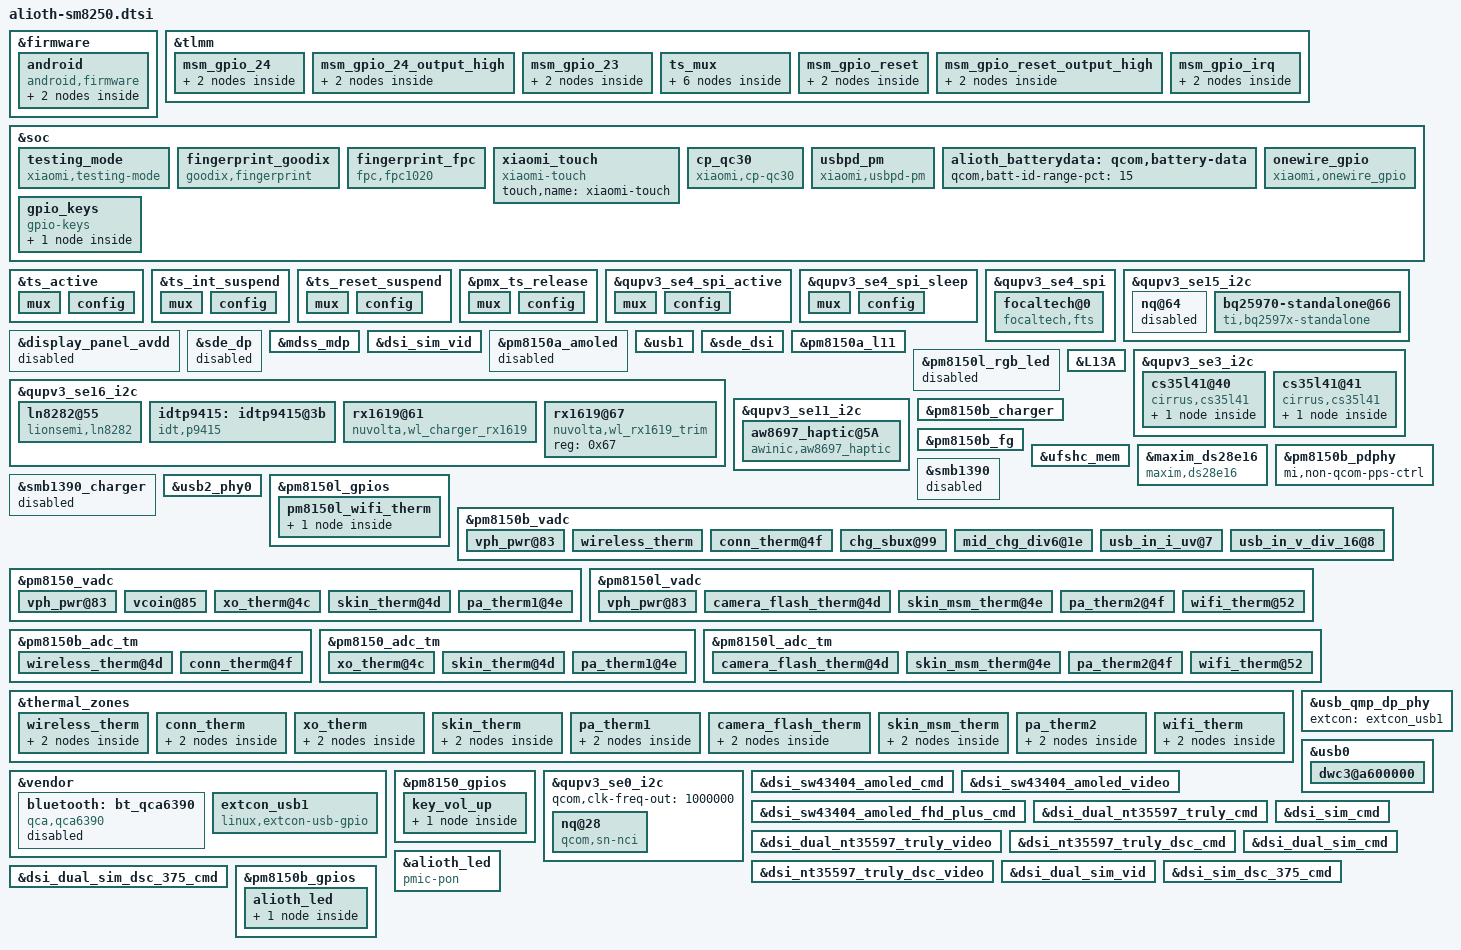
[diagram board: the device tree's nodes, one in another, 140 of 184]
/*
this file is for attribution only of alioth
*/

#include "alioth-pinctrl.dtsi"
#include "xiaomi-sm8250-common.dtsi"
#include "alioth-audio-overlay.dtsi"

&firmware {
	android {
		compatible = "android,firmware";
		vbmeta {
			compatible = "android,vbmeta";
			parts = "vbmeta,boot,system,vendor,dtbo";
		};

		fstab {
			compatible = "android,fstab";
		};
	};
};

/*IC int pin, rst pin init*/
&tlmm {
        /* GPIO_24: FP_RESET_N */
        msm_gpio_24: msm_gpio_24 {
                mux {
                         pins = "gpio24";
                         function = "gpio";
                };
                config {
                        pins = "gpio24";
                        drive-strength = <2>;
                        bias-disable;
                        output-low;
                };
        };
        /* GPIO_24 : FP_RESET_N, state device active*/
        msm_gpio_24_output_high: msm_gpio_24_output_high {
                mux {
                        pins = "gpio24";
                        function = "gpio";
                };
                config {
                        pins = "gpio24";
                        drive-strength = <2>;
                        bias-disable;
                        output-high;
                };
        };
        /* GPIO_23 : FP_INT_N */
        msm_gpio_23: msm_gpio_23 {
                mux {
                        pins = "gpio23";
                        function = "gpio";
                };
                config {
                        pins = "gpio23";
                        drive-strength = <2>;
                        bias-pull-down;
                };
        };

};

&soc {

	testing_mode {
		compatible = "xiaomi,testing-mode";
		status-gpio = <&tlmm 70 0x00>;
		debounce-time = <30>;
		pinctrl-names = "default";
		pinctrl-0 = <&test_mode_irq>;
	};

};

&ts_active {
	mux {
		pins = "gpio33", "gpio39";
		function = "gpio";
	};

	config {
		pins = "gpio33", "gpio39";
		drive-strength = <8>;
		bias-pull-up;
	};
};

&ts_int_suspend {
	mux {
		pins = "gpio39";
		function = "gpio";
	};

	config {
		pins = "gpio39";
		drive-strength = <2>;
		bias-pull-down;
	};
};

&ts_reset_suspend {
	mux {
		pins = "gpio33";
		function = "gpio";
	};

	config {
		pins = "gpio33";
		drive-strength = <2>;
		bias-pull-down;
	};
};

&pmx_ts_release {
	mux {
		pins = "gpio33", "gpio39";
		function = "gpio";
	};

	config {
		pins = "gpio33", "gpio39";
		drive-strength = <2>;
		bias-disable;
	};
};
&tlmm {
	ts_mux {
		ts_cs_active: ts_cs_active {
			mux {
				pins = "gpio11";
				function = "qup4";
			};

			config {
				pins = "gpio11";
				drive-strength = <16>;
				bias-pull-up;
			};
		};

		ts_cs_suspend: ts_cs_suspend {
			mux {
				pins = "gpio11";
				function = "gpio";
			};

			config {
				pins = "gpio11";
				drive-strength = <16>;
				bias-pull-up;
			};
		};
	};
};


&qupv3_se4_spi_active {
	mux {
		pins = "gpio8", "gpio9", "gpio10";
		function = "qup4";
	};

	config {
		pins = "gpio8", "gpio9", "gpio10";
		drive-strength = <6>;
		bias-pull-down;
	};
};

&qupv3_se4_spi_sleep {
	mux {
		pins = "gpio8", "gpio9", "gpio10";
		function = "gpio";
	};

	config {
		pins = "gpio8", "gpio9", "gpio10";
		drive-strength = <6>;
		bias-pull-down;
	};
};


&qupv3_se4_spi {
	status = "ok";
	pinctrl-0 = <&qupv3_se4_spi_active &ts_cs_active>;
	pinctrl-1 = <&qupv3_se4_spi_sleep &ts_cs_suspend>;
	focaltech@0 {
		status = "ok";
		compatible = "focaltech,fts";
		reg = <0x0>;
		spi-max-frequency = <10000000>;
		interrupt-parent = <&tlmm>;
		interrupts = <39 0x2008>;
		pinctrl-names = "pmx_ts_active", "pmx_ts_suspend", "pmx_ts_release";
		pinctrl-0 = <&ts_active>;
		pinctrl-1 = <&ts_int_suspend &ts_reset_suspend>;
		pinctrl-2 = <&pmx_ts_release>;
		vdd-supply = <&L10C>;
		vcc_i2c-supply = <&L1C>;
		focaltech,reset-gpio = <&tlmm 33 0x00>;
		focaltech,irq-gpio = <&tlmm 39 0x2008>;
		focaltech,max-touch-number = <10>;
		focaltech,display-coords = <0 0 8640 19200>;
		focaltech,open-min = <3000>;
		focaltech,touch-range-array = <1 5 10 15 20>;
		focaltech,touch-def-array = <3 3 3 3>;
		focaltech,touch-expert-array = <10 10 10 10
						20 20 15 10
						20 20 20 10>;
	};
};

&qupv3_se15_i2c {
	status = "ok";
	nq@64 {
		status = "disabled";
	};
};

&display_panel_avdd {
	status = "disabled";
};

&sde_dp {
	status = "disabled";
};

&mdss_mdp {
	connectors = <&sde_wb &sde_dsi &sde_dsi1 &sde_rscc>;
};

&dsi_sim_vid {
	qcom,panel-supply-entries = <&dsi_panel_pwr_supply_vci>;
	qcom,platform-reset-gpio = <&tlmm 12 0>;
};

&pm8150a_amoled {
	status = "disabled";
};

&usb1 {
        extcon = <&extcon_usb1>;
};

&sde_dsi {
	/delete-property/ vdd-supply;
	/delete-property/ avdd-supply;
	qcom,dsi-default-panel = <&dsi_sim_vid>;
	vci-supply = <&pm8150a_l11>;
};

&pm8150a_l11 {
	qcom,init-voltage = <3000000>;
	regulator-min-microvolt = <3000000>;
	regulator-max-microvolt = <3000000>;
};

&pm8150l_rgb_led {
	status = "disabled";
};

&soc {
	fingerprint_goodix {
		compatible = "goodix,fingerprint";
		goodix,gpio-reset = <&tlmm 24 GPIO_ACTIVE_LOW>;
		goodix,gpio-irq = <&tlmm 23 GPIO_ACTIVE_HIGH>;
		fp_vdd_vreg-supply = <&pm8150_l13>;
		status = "ok";
	};

	fingerprint_fpc {
		status = "ok";
		compatible = "fpc,fpc1020";
		interrupt-parent = <&tlmm>;
		interrupts = <23 0x0>;
		fpc,gpio_rst    = <&tlmm 24 0x0>;
		fpc,gpio_irq    = <&tlmm 23 0x0>;
		fp_vdd_vreg-supply = <&L13A>;
		pinctrl-names = "fpc1020_reset_reset",
			"fpc1020_reset_active",
			"fpc1020_irq_active";

		pinctrl-0 = <&msm_gpio_24>;
		pinctrl-1 = <&msm_gpio_24_output_high>;
		pinctrl-2 = <&msm_gpio_23>;

	};

/*
	fingerprint_3P0_VREG: fingerprint_3P0_VREG {
		compatible = "regulator-fixed";
		regulator-name = "fingerprint_3P0_VREG";
		startup-delay-us = <4000>;
		enable-active-high;
		gpio = <&tlmm 10 0>;
		regulator-always-on;
	};
*/
	xiaomi_touch {
		compatible = "xiaomi-touch";
		status = "ok";
		touch,name = "xiaomi-touch";
	};

};

&L13A {
	regulator-min-microvolt = <3304000>;
	regulator-max-microvolt = <3304000>;
	qcom,init-voltage = <3304000>;
	regulator-always-on;
};

&tlmm {
		/* FP_RESET_N */
	msm_gpio_reset: msm_gpio_reset {
		mux {
			pins = "gpio24";
			function = "gpio";
		};
		config {
			pins = "gpio24";
			drive-strength = <2>;
			bias-disable;
			output-low;
		};
	};
		/* FP_RESET_N, state device active*/
	msm_gpio_reset_output_high: msm_gpio_reset_output_high {
		mux {
			pins = "gpio24";
			function = "gpio";
		};
		config {
			pins = "gpio24";
			drive-strength = <2>;
			bias-disable;
			output-high;
		};
	};
		/* FP_INT_N */
	msm_gpio_irq: msm_gpio_irq {
		mux {
			pins = "gpio23";
			function = "gpio";
		};
		config {
			pins = "gpio23";
			drive-strength = <2>;
			bias-pull-down;
		};
	};
};

&qupv3_se15_i2c {
	#address-cells = <1>;
	#size-cells = <0>;
	status = "ok";
	bq25970-standalone@66 {
		compatible = "ti,bq2597x-standalone";
		reg = <0x66>;
		interrupt-parent = <&tlmm>;
		interrupts = <68 0x2002>;
		pinctrl-names = "default";
		pinctrl-0 = <&bq2597x_master_int_default>;

		/*ti,bq2597x,bat-ovp-disable;*/
		ti,bq2597x,bat-ovp-alarm-disable;
		ti,bq2597x,bat-ocp-disable;
		ti,bq2597x,bat-ocp-alarm-disable;
		ti,bq2597x,bat-ucp-alarm-disable;
		ti,bq2597x,bat-ucp-disable;

		/*ti,bq2597x,bus-ovp-alarm-disable;
		ti,bq2597x,bus-ocp-disable;
		ti,bq2597x,bus-ocp-alarm-disable;*/
		ti,bq2597x,bat-therm-disable;
		ti,bq2597x,bus-therm-disable;
		ti,bq2597x,die-therm-disable;

		ti,bq2597x,bat-ovp-threshold = <4525>;
		ti,bq2597x,bat-ovp-alarm-threshold = <4525>;
		//ti,bq2597x,bat-ocp-threshold = <8000>;
		//ti,bq2597x,bat-ocp-alarm-threshold = <7500>;

		ti,bq2597x,bus-ovp-threshold = <12000>;
		ti,bq2597x,bus-ovp-alarm-threshold = <11000>;
		ti,bq2597x,bus-ocp-threshold = <3750>;
		ti,bq2597x,bus-ocp-alarm-threshold = <3500>;

		//ti,bq2597x,bat-ucp-alarm-threshold = <2000>;

		ti,bq2597x,bat-therm-threshold = <0x15>;/*4.1%*/
		ti,bq2597x,bus-therm-threshold = <0x15>;/*4.1%*/
		ti,bq2597x,die-therm-threshold = <145>;

		ti,bq2597x,ac-ovp-threshold = <14>;
		//ti,bq2597x,sense-resistor-mohm = <2>;
	};
};

&qupv3_se16_i2c {
	status = "ok";
	ln8282@55 {
		compatible = "lionsemi,ln8282";
		status = "ok";
		reg = <0x55>;
		ln,enable = <&tlmm 156 0x00>;
		ln,irq = <&tlmm 158 0x00>;
		pinctrl-names = "ln8282_active","ln8282_suspend";
		pinctrl-0 = <&ln8282_enable_active>;
		pinctrl-1 = <&ln8282_enable_suspend>;
	};

	idtp9415: idtp9415@3b {
		compatible = "idt,p9415";
		status = "ok";
		reg = <0x3b>;
		idt,irq = <&tlmm 157 0x00>;
		idt,enable = <&tlmm 155 0x00>;
		idt,reverse-enable = <&tlmm 154 0x00>;
		idt,wpc-det = <&pm8150b_gpios 7 GPIO_ACTIVE_HIGH>;
		pinctrl-names = "default", "idt_active", "idt_suspend";
		pinctrl-0 = <&power_good_default>;
		pinctrl-1 = <&idt_int_active &idt_enable_active &txon_enable_active>;
		pinctrl-2 = <&idt_int_suspend &idt_enable_suspend &txon_enable_suspend>;
		mi,wireless-by-usbin;
		mi,only-idt-on-cmi;
	};

	rx1619@61 {
		compatible = "nuvolta,wl_charger_rx1619";
		reg = <0x61>;
		status = "ok";
		rx,irq_gpio = <&tlmm 157 0x00>;
		rx,tx_on_gpio = <&tlmm 154 0x00>;
		rx,power_good = <&pm8150b_gpios 7 GPIO_ACTIVE_HIGH>;
		rx,enable = <&tlmm 155 0x00>;
		pinctrl-names = "default","nu_active","nu_suspend";
		pinctrl-0 = <&power_good_default>;
		pinctrl-1 = <&nu_int_active &txon_enable_active &nu_sleep_active>;
		pinctrl-2 = <&nu_int_suspend &txon_enable_suspend &nu_sleep_suspend>;
		mi,wireless-by-usbin;
	};

	rx1619@67 {
		compatible = "nuvolta,wl_rx1619_trim";
		reg = <0x67>;
		status = "ok";
	};
};

&qupv3_se3_i2c {
	status = "ok";

        /* Speaker */
	cs35l41@40 {
		#sound-dai-cells = <1>;
		compatible = "cirrus,cs35l41";
		reset-gpios = <&tlmm 114 0>;
		reg = <0x40>;
		pinctrl-names = "cs35l41_irq_speaker";
		pinctrl-0 = <&cs35l41_int_speaker>;
		interrupt-parent = <&tlmm>;
		interrupts = <113 8>;
		cirrus,temp-warn_threshold = <3>;
		cirrus,boost-peak-milliamp = <4000>;
		cirrus,boost-ind-nanohenry = <1000>;
		cirrus,boost-cap-microfarad = <15>;
		cirrus,asp-sdout-hiz = <3>;
		//cirrus,right-channel-amp;
		sound-name-prefix = "RCV";
		cirrus,gpio-config2 {
			cirrus,gpio-src-select = <0x4>;
			cirrus,gpio-output-enable;
		};

	};
	/* Receiver */
	cs35l41@41 {
		#sound-dai-cells = <1>;
		compatible = "cirrus,cs35l41";
		reset-gpios = <&tlmm 114 0>;
		reg = <0x41>;
		pinctrl-names = "cs35l41_irq_speaker_rcv";
		pinctrl-0 = <&cs35l41_int_speaker_rcv>;
		interrupt-parent = <&tlmm>;
		interrupts = <112 8>;
		cirrus,temp-warn_threshold = <3>;
		cirrus,boost-peak-milliamp = <4000>;
		cirrus,boost-ind-nanohenry = <1000>;
		cirrus,boost-cap-microfarad = <15>;
		cirrus,right-channel-amp;
		cirrus,asp-sdout-hiz = <3>;
		//sound-name-prefix = "RCV";
		cirrus,gpio-config2 {
			cirrus,gpio-src-select = <0x4>;
			cirrus,gpio-output-enable;
		};

	};

};

&qupv3_se11_i2c {
	status = "ok";
	aw8697_haptic@5A {
		compatible = "awinic,aw8697_haptic";
		vib_bst_vol_default = < 0x11 >;
		vib_bst_vol_ram = < 0x11 >;
		vib_bst_vol_rtp = < 0x11 >;
		status = "ok";
	};
};
&pm8150b_charger {
	status = "ok";
	qcom,sec-charger-config = <0>;
	qcom,usb-icl-ua = <3000000>;
	qcom,fcc-max-ua = <5400000>;
	qcom,fv-max-uv = <4480000>;
	qcom,non-fcc-fv-max-uv = <4450000>;
	qcom,dc-icl-ua = <1000000>;
	qcom,auto-recharge-soc = <99>;
	qcom,chg-term-src = <1>;
	qcom,chg-term-current-ma = <(-220)>;
	//qcom,step-charging-enable;
	qcom,sw-jeita-enable;
	qcom,chg-warm-th= <450>;
	qcom,chg-cool-th= <150>;
	//qcom,suspend-input-on-debug-batt;
	qcom,usbpd-phandle = <&pm8150b_pdphy>;
	qcom,battery-data = <&alioth_batterydata>;
	mi,six-pin-step-chg-params = <4200000  5400000
				4450000  5400000
				4480000  4000000>;
	mi,six-pin-step-chg;
	mi,six-pin-soc-th = <85>;
	mi,fcc-batt-unverify-ua = <2000000>;
	mi,support-ffc;
	qcom,lpd-disable;
	mi,use-bq-pump;
	qcom,disable-suspend-on-collapse;
	qcom,distinguish-qc-class-ab;
//	qcom,support-conn-therm;
//	vbus-disable-gpio = <&tlmm 6 GPIO_ACTIVE_HIGH>;
//	pinctrl-names = "default", "vbus_disable_active", "vbus_disable_suspend";
//	pinctrl-0 = <&vbus_disable_suspend>;
//	pinctrl-1 = <&vbus_disable_active>;
//	pinctrl-2 = <&vbus_disable_suspend>;

	io-channels = <&pm8150b_vadc ADC_USB_IN_V_16>,
			<&pm8150b_vadc ADC_MID_CHG_DIV6>,
			<&pm8150b_vadc ADC_USB_IN_I>,
			<&pm8150b_vadc ADC_SBUx>,
			<&pm8150b_vadc ADC_VPH_PWR>,
			<&pm8150b_vadc ADC_AMUX_THM3_PU2>,
			<&pm8150b_vadc ADC_CHG_TEMP>;
	io-channel-names = "usb_in_voltage",
			"mid_voltage",
			"usb_in_current",
			"sbux_res",
			"vph_voltage",
			"conn_temp",
			"chg_temp";
	qcom,thermal-mitigation = <3000000 2800000 2600000 2400000 2200000 2100000 2000000
				   1800000 1600000 1500000 1400000 1200000 1000000 900000
				   800000 500000>;
	qcom,thermal-mitigation-icl
				= <2800000 2700000 2600000 2400000 2200000 2100000 2000000
				   1800000 1600000 1500000 1400000 1300000 1200000 1100000
				   950000 750000>;
	qcom,thermal-mitigation-dcp
				= <1800000 1800000 1800000 1800000 1800000 1800000 1800000
				   1800000 1800000 1700000 1600000 1400000 1200000 1100000
				   1100000 1000000>;
	qcom,thermal-mitigation-qc2
				= <1500000 1500000 1500000 1500000 1450000 1400000 1350000
				   1300000 1150000 1100000 1000000 900000 850000 750000
				   650000 500000>;
	qcom,thermal-fcc-qc3-normal
				= <3200000 3000000 2800000 2600000 2500000 2400000 2300000
				   2200000 2100000 1800000 1600000 1400000 1200000 1000000
				   750000 750000>;
	qcom,thermal-fcc-qc3-cp
				= <4800000 4600000 4400000 4200000 4000000 3800000 3600000
				   3400000 3000000 2600000 2400000 2200000 2000000 1300000
				   1000000 700000>;
	qcom,thermal-fcc-qc3-classb-cp
				= <5100000 4700000 4300000 4000000 3600000 3500000 3400000
				   3400000 3400000 3200000 2500000 2200000 2000000 700000
				   300000 100000>;
	qcom,thermal-mitigation-pd-base
				= <3000000 2800000 2600000 2400000 2200000 2000000 1800000
				   1600000 1600000 1400000 1200000 1100000 1050000 1000000
				   950000 500000>;
	qcom,thermal-fcc-pps-bq
				= <5400000 5300000 5200000 4900000 4800000 4500000 4200000
				   4000000 3800000 3500000 3200000 3000000 2500000 2000000
				   1500000 1000000>;
};

&pm8150b_fg {
	qcom,battery-data = <&alioth_batterydata>;
	qcom,rapid-soc-dec-en;
	qcom,five-pin-battery;
	qcom,soc-hi-res;
	qcom,sun-profile-only;
	qcom,soc_decimal_rate = <
		0  38
		10 35
		20 33
		30 33
		40 33
		50 33
		60 33
		70 30
		80 25
		90 20
		95 10 >;
	qcom,fg-sys-term-current = <(-500)>;
	qcom,fg-ffc-sys-term-current = <(-1500)>;
	qcom,ki-coeff-low-chg = <315>;
	qcom,ki-coeff-med-chg = <183>;
	qcom,fg-cutoff-voltage = <3400>;
	qcom,fg-cutoff-voltage-global = <3400>;
	qcom,fg-cutoff-current = <200>;
	qcom,fg-empty-voltage = <3100>;
	qcom,fg-batt-temp-hyst = <1>;
	qcom,fg-batt-temp-delta = <6>;
	qcom,soc-scale-vbatt-mv = <3600>;
	qcom,fg-force-load-profile;
	qcom,ki-coeff-chg-med-hi-thresh-ma = <1000>;
	qcom,ki-coeff-chg-low-med-thresh-ma = <500>;
	qcom,ffc-ki-coeff-chg-med-hi-thresh-ma = <3900>;
	qcom,ffc-ki-coeff-chg-low-med-thresh-ma = <3500>;
	qcom,fg-esr-cal-soc-thresh = <50 90>;
	qcom,fg-esr-cal-temp-thresh = <10 40>;
	qcom,fg-esr-timer-chg-fast = <0 7>;
	qcom,fg-esr-timer-dischg-fast = <0 7>;
	qcom,fg-esr-timer-chg-slow = <0 96>;
	qcom,fg-esr-timer-dischg-slow = <0 96>;
	qcom,fg-esr-cal-soc-thresh-2 = <50 4000>;
	qcom,fg-esr-cal-temp-thresh-2 = <10 40>;
	qcom,fg-esr-timer-chg-fast-2 = <0 7>;
	qcom,fg-esr-timer-dischg-fast-2 = <0 7>;
	qcom,fg-esr-timer-chg-slow-2 = <0 96>;
	qcom,fg-esr-timer-dischg-slow-2 = <0 96>;
	qcom,fg-esr-flt-sel = <2>;
	qcom,fg-esr-pulse-thresh-ma = <40>;
	qcom,fg-esr-meas-curr-ma = <60>;
	qcom,fg-ffc-esr-pulse-thresh-ma = <120>;
	qcom,fg-ffc-esr-meas-curr-ma = <100>;
	//qcom,fg-increase-100soc-time;
	qcom,fg-increase-100soc-time-2;
	qcom,shutdown-delay-enable;
};

&soc {
	cp_qc30 {
		compatible = "xiaomi,cp-qc30";
		status = "ok";
		mi,qc3-bat-volt-max = <4480>;
		mi,qc3-bat-curr-max = <3600>;
		mi,qc3-bus-volt-max = <12000>;
		mi,qc3-bus-curr-max = <2100>;
		mi,qc3-battery-warm-th = <450>;
		mi,use-qcom-gauge;
		mi,support-qc3p5-without-smb;
		//mi,cp-sec-enable;
	};

	usbpd_pm {
		compatible = "xiaomi,usbpd-pm";
		status = "ok";
		mi,pd-bat-volt-max = <4480>;
		mi,pd-bat-curr-max = <12500>;
		mi,pd-bus-volt-max = <12000>;
		mi,pd-bus-curr-max = <3000>;
		mi,pd-bus-curr-compensate  = <0>;
		mi,pd-non-ffc-bat-volt-max = <4450>;
		mi,pd-battery-warm-th = <450>;
		mi,step-charge-high-vol-curr-max = <5400000>;
		mi,use-qcom-gauge;
		//mi,cp-sec-enable;
		mi,therm-level-threshold = <12>;
	};

	alioth_batterydata: qcom,battery-data {
		qcom,batt-id-range-pct = <15>;
		#include "fg-gen4-batterydata-apollo-sun-5000mah.dtsi"
		#include "fg-gen4-batterydata-alioth-sunwoda-5000mah.dtsi"
		#include "fg-gen4-batterydata-alioth-atl-5000mah.dtsi"
	};

	onewire_gpio: onewire_gpio {
		compatible = "xiaomi,onewire_gpio";
		label = "xm_onewire";
		xiaomi,version = <1>;
		xiaomi,ow_gpio = <&tlmm 25 0x00>;
		mi,onewire-gpio-cfg-addr = <0x0F519000 0x4>;
		xiaomi,gpio_number = <25>;
		pinctrl-names = "onewire_active", "onewire_sleep";
		pinctrl-0 = <&onewire_gpio_active>;
		pinctrl-1 = <&onewire_gpio_sleep>;
		status = "ok";
	};
};

&ufshc_mem {
	vccq_set_npm = /bits/ 16 <0x1AD>;

	hsg4_synclength = /bits/ 16 <0x145 0x4F
				     0x1AD 0x4F
				     0x12C 0x4F>;

	status = "ok";
};

&maxim_ds28e16 {
	compatible = "maxim,ds28e16";
	label = "max_ds28e16";
	maxim,version = <1>;
	status = "ok";
	mi,factory-enable;
};

&pm8150b_pdphy {
	mi,non-qcom-pps-ctrl;
};

&smb1390 {
	status = "disabled";
};

&smb1390_charger {
	status = "disabled";
};

&usb2_phy0 {
	qcom,param-override-seq =
		<0xE5 0x6C
		 0xfa 0x70
		 0x2c 0x74>;
	qcom,global-param-override-seq =
		<0xE5 0x6C
		 0xfa 0x70
		 0x2c 0x74>;
};

&pm8150l_gpios {
	pm8150l_wifi_therm {
		pm8150l_wifi_therm_default: pm8150l_wifi_therm_default {
			pins = "gpio5";
			bias-high-impedance;
		};
	};
};

&pm8150b_vadc {
	#address-cells = <1>;
	#size-cells = <0>;

	vph_pwr@83 {
		reg = <ADC_VPH_PWR>;
		label = "vph_pwr";
		qcom,pre-scaling = <1 3>;
	};

	wireless_therm {
		reg = <ADC_AMUX_THM1_PU2>;
		label = "wireless_therm";
		qcom,ratiometric;
		qcom,hw-settle-time = <200>;
		qcom,pre-scaling = <1 1>;
	};

	conn_therm@4f {
		reg = <ADC_AMUX_THM3_PU2>;
		label = "conn_therm";
		qcom,ratiometric;
		qcom,hw-settle-time = <200>;
		qcom,pre-scaling = <1 1>;
	};

	chg_sbux@99 {
		reg = <ADC_SBUx>;
		label = "chg_sbux";
		qcom,pre-scaling = <1 3>;
	};

	mid_chg_div6@1e {
		reg = <ADC_MID_CHG_DIV6>;
		label = "chg_mid";
		qcom,pre-scaling = <1 6>;
	};

	usb_in_i_uv@7 {
		reg = <ADC_USB_IN_I>;
		label = "usb_in_i_uv";
		qcom,pre-scaling = <1 1>;
	};

	usb_in_v_div_16@8 {
		reg = <ADC_USB_IN_V_16>;
		label = "usb_in_v_div_16";
		qcom,pre-scaling = <1 16>;
	};
};

&pm8150_vadc {
	#address-cells = <1>;
	#size-cells = <0>;

	vph_pwr@83 {
		reg = <ADC_VPH_PWR>;
		label = "vph_pwr";
		qcom,pre-scaling = <1 3>;
	};

	vcoin@85 {
		reg = <ADC_VCOIN>;
		label = "vcoin";
		qcom,pre-scaling = <1 3>;
	};

	xo_therm@4c {
		reg = <ADC_XO_THERM_PU2>;
		label = "xo_therm";
		qcom,ratiometric;
		qcom,hw-settle-time = <200>;
		qcom,pre-scaling = <1 1>;
	};

	skin_therm@4d {
		reg = <ADC_AMUX_THM1_PU2>;
		label = "skin_therm";
		qcom,ratiometric;
		qcom,hw-settle-time = <200>;
		qcom,pre-scaling = <1 1>;
	};

	pa_therm1@4e {
		reg = <ADC_AMUX_THM2_PU2>;
		label = "pa_therm1";
		qcom,ratiometric;
		qcom,hw-settle-time = <200>;
		qcom,pre-scaling = <1 1>;
	};
};

&pm8150l_vadc {
	#address-cells = <1>;
	#size-cells = <0>;

	vph_pwr@83 {
		reg = <ADC_VPH_PWR>;
		label = "vph_pwr";
		qcom,pre-scaling = <1 3>;
	};

	camera_flash_therm@4d {
		reg = <ADC_AMUX_THM1_PU2>;
		label = "camera_flash_therm";
		qcom,ratiometric;
		qcom,hw-settle-time = <200>;
		qcom,pre-scaling = <1 1>;
	};

	skin_msm_therm@4e {
		reg = <ADC_AMUX_THM2_PU2>;
		label = "skin_msm_therm";
		qcom,ratiometric;
		qcom,hw-settle-time = <200>;
		qcom,pre-scaling = <1 1>;
	};

	pa_therm2@4f {
		reg = <ADC_AMUX_THM3_PU2>;
		label = "pa_therm2";
		qcom,ratiometric;
		qcom,hw-settle-time = <200>;
		qcom,pre-scaling = <1 1>;
	};

	wifi_therm@52 {
		reg = <ADC_GPIO1_PU2>;
		label = "wifi_therm";
		qcom,ratiometric;
		qcom,hw-settle-time = <200>;
		qcom,pre-scaling = <1 1>;
	};
};

&pm8150b_adc_tm {
	#address-cells = <1>;
	#size-cells = <0>;

	io-channels = <&pm8150b_vadc ADC_AMUX_THM1_PU2>,
			<&pm8150b_vadc ADC_AMUX_THM3_PU2>;

	wireless_therm@4d {
		reg = <ADC_AMUX_THM1_PU2>;
		qcom,ratiometric;
		qcom,hw-settle-time = <200>;
	};

	conn_therm@4f {
		reg = <ADC_AMUX_THM3_PU2>;
		qcom,ratiometric;
		qcom,hw-settle-time = <200>;
	};
};

&pm8150_adc_tm {
	#address-cells = <1>;
	#size-cells = <0>;

	io-channels = <&pm8150_vadc ADC_XO_THERM_PU2>,
			<&pm8150_vadc ADC_AMUX_THM1_PU2>,
			<&pm8150_vadc ADC_AMUX_THM2_PU2>;

	xo_therm@4c {
		reg = <ADC_XO_THERM_PU2>;
		qcom,ratiometric;
		qcom,hw-settle-time = <200>;
	};

	skin_therm@4d {
		reg = <ADC_AMUX_THM1_PU2>;
		qcom,ratiometric;
		qcom,hw-settle-time = <200>;
	};

	pa_therm1@4e {
		reg = <ADC_AMUX_THM2_PU2>;
		qcom,ratiometric;
		qcom,hw-settle-time = <200>;
	};
};

&pm8150l_adc_tm {
	#address-cells = <1>;
	#size-cells = <0>;

	camera_flash_therm@4d {
		reg = <ADC_AMUX_THM1_PU2>;
		qcom,ratiometric;
		qcom,hw-settle-time = <200>;
	};

	skin_msm_therm@4e {
		reg = <ADC_AMUX_THM2_PU2>;
		qcom,ratiometric;
		qcom,hw-settle-time = <200>;
	};

	pa_therm2@4f {
		reg = <ADC_AMUX_THM3_PU2>;
		qcom,ratiometric;
		qcom,hw-settle-time = <200>;
	};

	wifi_therm@52 {
		reg = <ADC_GPIO1_PU2>;
		qcom,ratiometric;
		qcom,hw-settle-time = <200>;
	};
};

&thermal_zones {
	wireless_therm {//place close to wireless charge RX ic
		polling-delay-passive = <0>;
		polling-delay = <0>;
		thermal-governor = "user_space";
		thermal-sensors = <&pm8150b_adc_tm ADC_AMUX_THM1_PU2>;
		wake-capable-sensor;
		trips {
			active-config0 {
				temperature = <125000>;
				hysteresis = <1000>;
				type = "passive";
			};
		};
	};

	conn_therm {//place close to type-c connector
		polling-delay-passive = <0>;
		polling-delay = <0>;
		thermal-governor = "user_space";
		thermal-sensors = <&pm8150b_adc_tm ADC_AMUX_THM3_PU2>;
		wake-capable-sensor;
		trips {
			active-config0 {
				temperature = <125000>;
				hysteresis = <1000>;
				type = "passive";
			};
		};
	};

	xo_therm {
		polling-delay-passive = <0>;
		polling-delay = <0>;
		thermal-governor = "user_space";
		thermal-sensors = <&pm8150_adc_tm ADC_XO_THERM_PU2>;
		wake-capable-sensor;
		trips {
			active-config0 {
				temperature = <125000>;
				hysteresis = <1000>;
				type = "passive";
			};
		};
	};

	skin_therm {
		polling-delay-passive = <0>;
		polling-delay = <0>;
		thermal-governor = "user_space";
		thermal-sensors = <&pm8150_adc_tm ADC_AMUX_THM1_PU2>;
		wake-capable-sensor;
		trips {
			active-config0 {
				temperature = <125000>;
				hysteresis = <1000>;
				type = "passive";
			};
		};
	};

	pa_therm1 {
		polling-delay-passive = <0>;
		polling-delay = <0>;
		thermal-governor = "user_space";
		thermal-sensors = <&pm8150_adc_tm ADC_AMUX_THM2_PU2>;
		wake-capable-sensor;
		trips {
			active-config0 {
				temperature = <125000>;
				hysteresis = <1000>;
				type = "passive";
			};
		};
	};

	camera_flash_therm {
		polling-delay-passive = <0>;
		polling-delay = <0>;
		thermal-governor = "user_space";
		thermal-sensors = <&pm8150l_adc_tm ADC_AMUX_THM1_PU2>;
		wake-capable-sensor;
		trips {
			active-config0 {
				temperature = <125000>;
				hysteresis = <1000>;
				type = "passive";
			};
		};
	};

	skin_msm_therm {
		polling-delay-passive = <0>;
		polling-delay = <0>;
		thermal-governor = "user_space";
		thermal-sensors = <&pm8150l_adc_tm ADC_AMUX_THM2_PU2>;
		wake-capable-sensor;
		trips {
			active-config0 {
				temperature = <125000>;
				hysteresis = <1000>;
				type = "passive";
			};
		};
	};

	pa_therm2 {
		polling-delay-passive = <0>;
		polling-delay = <0>;
		thermal-governor = "user_space";
		thermal-sensors = <&pm8150l_adc_tm ADC_AMUX_THM3_PU2>;
		wake-capable-sensor;
		trips {
			active-config0 {
				temperature = <125000>;
				hysteresis = <1000>;
				type = "passive";
			};
		};
	};

	wifi_therm {
		polling-delay-passive = <0>;
		polling-delay = <0>;
		thermal-governor = "user_space";
		thermal-sensors = <&pm8150l_adc_tm ADC_GPIO1_PU2>;
		wake-capable-sensor;
		trips {
			active-config0 {
				temperature = <125000>;
				hysteresis = <1000>;
				type = "passive";
			};
		};
	};
};

&vendor {
	bluetooth: bt_qca6390 {
		compatible = "qca,qca6390";
		pinctrl-names = "default";
		pinctrl-0 = <&bt_en_sleep>;
		qca,bt-reset-gpio = <&tlmm 21 0>; /* BT_EN */
		qca,wl-reset-gpio = <&tlmm 20 0>; /* WL_EN */
		qca,bt-vdd-aon-supply = <&pm8150_s6>;
		qca,bt-vdd-dig-supply = <&pm8150_s6>;
		qca,bt-vdd-rfa1-supply = <&pm8150_s5>;
		qca,bt-vdd-rfa2-supply = <&pm8150a_s8>;
		qca,bt-vdd-asd-supply = <&pm8150_l16>;

		qca,bt-vdd-aon-voltage-level = <950000 950000>;
		qca,bt-vdd-dig-voltage-level = <950000 952000>;
		qca,bt-vdd-rfa1-voltage-level = <1900000 1900000>;
		qca,bt-vdd-rfa2-voltage-level = <1350000 1350000>;
		qca,bt-vdd-asd-voltage-level = <3024000 3304000>;

		qca,bt-vdd-aon-current-level = <0>;
		qca,bt-vdd-dig-current-level = <0>;
		qca,bt-vdd-rfa1-current-level = <0>;
		qca,bt-vdd-rfa2-current-level = <0>;
		qca,bt-vdd-asd-current-level = <0>;
		status = "disabled";
	};

	extcon_usb1: extcon_usb1 {
		compatible = "linux,extcon-usb-gpio";
		vbus-gpio = <&pm8150_gpios 10 GPIO_ACTIVE_HIGH>;
		id-gpio = <&tlmm 91 GPIO_ACTIVE_HIGH>;
		vbus-out-gpio = <&pm8150_gpios 9 GPIO_ACTIVE_HIGH>;

		pinctrl-names = "default";
		pinctrl-0 = <&usb2_vbus_det_default
			     &usb2_id_det_default
			     &usb2_vbus_boost_default>;
	};
};

&usb_qmp_dp_phy {
	extcon = <&extcon_usb1>;
};

&usb2_phy0 {
	qcom,param-override-seq =
		<0xE5 0x6C
		 0xfa 0x70
		 0x2c 0x74>;
	qcom,global-param-override-seq =
		<0xE5 0x6C
		 0xfa 0x70
		 0x2c 0x74>;
};

&usb0 {
	dwc3@a600000 {
		usb-phy = <&usb2_phy0>, <&usb_qmp_dp_phy>;
		maximum-speed = "super-speed";
	};
};

&usb1 {
	extcon = <&extcon_usb1>;
	dr_mode = "host";
	qcom,ignore-wakeup-src-in-hostmode;
};

&soc {
	gpio_keys {
		compatible = "gpio-keys";
		label = "gpio-keys";

		pinctrl-names = "default";
		pinctrl-0 = <&key_vol_up_default>;

		vol_up {
			label = "volume_up";
			gpios = <&pm8150_gpios 6 GPIO_ACTIVE_LOW>;
			linux,input-type = <1>;
			linux,code = <KEY_VOLUMEUP>;
			gpio-key,wakeup;
			debounce-interval = <15>;
			linux,can-disable;
		};
	};
};

&pm8150_gpios {
	key_vol_up {
		key_vol_up_default: key_vol_up_default {
			pins = "gpio6";
			function = "normal";
			input-enable;
			bias-pull-up;
			power-source = <1>;
		};
	};
};

&qupv3_se0_i2c {
	status = "ok";
	qcom,clk-freq-out = <1000000>;
	#address-cells = <1>;
	#size-cells = <0>;
	nq@28 {
		compatible = "qcom,sn-nci";
		reg = <0x28>;
		qcom,sn-irq = <&tlmm 111 0x00>;
		qcom,sn-ven = <&tlmm 6 0x00>;
		qcom,sn-firm = <&tlmm 110 0x00>;
		qcom,sn-clkreq = <&tlmm 7 0x00>;
		qcom,sn-vdd-1p8-supply = <&L1C>;
		qcom,sn-vdd-1p8-voltage = <1800000 1800000>;
		qcom,sn-vdd-1p8-current = <157000>;
		interrupt-parent = <&tlmm>;
		interrupts = <111 0>;
		interrupt-names = "nfc_irq";
		pinctrl-names = "nfc_active", "nfc_suspend";
		pinctrl-0 = <&nfc_int_active &nfc_enable_active>;
		pinctrl-1 = <&nfc_int_suspend &nfc_enable_suspend>;
	};
};

&dsi_sw43404_amoled_cmd {
	qcom,panel-supply-entries = <&dsi_panel_pwr_supply>;
	qcom,mdss-dsi-bl-pmic-control-type = "bl_ctrl_dcs";
	qcom,mdss-dsi-bl-min-level = <1>;
	qcom,mdss-dsi-bl-max-level = <1023>;
	qcom,mdss-brightness-max-level = <255>;
	qcom,platform-te-gpio = <&tlmm 66 0>;
	qcom,platform-reset-gpio = <&tlmm 75 0>;
	qcom,mdss-dsi-panel-test-pin = <&tlmm 46 0>;
};

&dsi_sw43404_amoled_video {
	qcom,panel-supply-entries = <&dsi_panel_pwr_supply>;
	qcom,mdss-dsi-bl-pmic-control-type = "bl_ctrl_dcs";
	qcom,mdss-dsi-bl-min-level = <1>;
	qcom,mdss-dsi-bl-max-level = <1023>;
	qcom,mdss-brightness-max-level = <255>;
	qcom,platform-reset-gpio = <&tlmm 75 0>;
	qcom,mdss-dsi-panel-test-pin = <&tlmm 46 0>;
};

&dsi_sw43404_amoled_fhd_plus_cmd {
	qcom,panel-supply-entries = <&dsi_panel_pwr_supply>;
	qcom,mdss-dsi-bl-pmic-control-type = "bl_ctrl_dcs";
	qcom,mdss-dsi-bl-min-level = <1>;
	qcom,mdss-dsi-bl-max-level = <1023>;
	qcom,mdss-brightness-max-level = <255>;
	qcom,platform-te-gpio = <&tlmm 66 0>;
	qcom,platform-reset-gpio = <&tlmm 75 0>;
	qcom,mdss-dsi-panel-test-pin = <&tlmm 46 0>;
};

&dsi_dual_nt35597_truly_cmd {
	qcom,panel-supply-entries = <&dsi_panel_pwr_supply>;
	qcom,mdss-dsi-bl-pmic-control-type = "bl_ctrl_external";
	qcom,platform-te-gpio = <&tlmm 66 0>;
	qcom,platform-reset-gpio = <&tlmm 75 0>;
	qcom,platform-en-gpio = <&tlmm 60 0>;
};

&dsi_dual_nt35597_truly_video {
	qcom,panel-supply-entries = <&dsi_panel_pwr_supply>;
	qcom,mdss-dsi-bl-pmic-control-type = "bl_ctrl_external";
	qcom,platform-reset-gpio = <&tlmm 75 0>;
	qcom,platform-en-gpio = <&tlmm 60 0>;
};

&dsi_nt35597_truly_dsc_cmd {
	qcom,panel-supply-entries = <&dsi_panel_pwr_supply>;
	qcom,mdss-dsi-bl-pmic-control-type = "bl_ctrl_external";
	qcom,platform-te-gpio = <&tlmm 66 0>;
	qcom,platform-reset-gpio = <&tlmm 75 0>;
};

&dsi_nt35597_truly_dsc_video {
	qcom,panel-supply-entries = <&dsi_panel_pwr_supply>;
	qcom,mdss-dsi-bl-pmic-control-type = "bl_ctrl_external";
	qcom,platform-reset-gpio = <&tlmm 75 0>;
};

&dsi_sim_cmd {
	qcom,panel-supply-entries = <&dsi_panel_pwr_supply>;
	qcom,mdss-dsi-bl-pmic-control-type = "bl_ctrl_dcs";
	qcom,platform-reset-gpio = <&tlmm 75 0>;
};

&dsi_sim_vid {
	qcom,panel-supply-entries = <&dsi_panel_pwr_supply>;
	qcom,mdss-dsi-bl-pmic-control-type = "bl_ctrl_dcs";
	qcom,platform-reset-gpio = <&tlmm 75 0>;
};

&dsi_dual_sim_cmd {
	qcom,panel-supply-entries = <&dsi_panel_pwr_supply>;
	qcom,mdss-dsi-bl-pmic-control-type = "bl_ctrl_dcs";
	qcom,platform-reset-gpio = <&tlmm 75 0>;
};

&dsi_dual_sim_vid {
	qcom,panel-supply-entries = <&dsi_panel_pwr_supply>;
	qcom,mdss-dsi-bl-pmic-control-type = "bl_ctrl_dcs";
	qcom,platform-reset-gpio = <&tlmm 75 0>;
};

&dsi_sim_dsc_375_cmd {
	qcom,panel-supply-entries = <&dsi_panel_pwr_supply>;
	qcom,mdss-dsi-bl-pmic-control-type = "bl_ctrl_dcs";
	qcom,platform-reset-gpio = <&tlmm 75 0>;
};

&dsi_dual_sim_dsc_375_cmd {
	qcom,panel-supply-entries = <&dsi_panel_pwr_supply>;
	qcom,mdss-dsi-bl-pmic-control-type = "bl_ctrl_dcs";
	qcom,platform-reset-gpio = <&tlmm 75 0>;
};

&dsi_sw43404_amoled_cmd {
	qcom,esd-check-enabled;
	qcom,mdss-dsi-panel-status-check-mode = "reg_read";
	qcom,mdss-dsi-panel-status-command = [06 01 00 01 00 00 01 0a];
	qcom,mdss-dsi-panel-status-command-state = "dsi_hs_mode";
	qcom,mdss-dsi-panel-status-value = <0x9c>;
	qcom,mdss-dsi-panel-status-read-length = <1>;
};

&dsi_sw43404_amoled_video {
	qcom,esd-check-enabled;
	qcom,mdss-dsi-panel-status-check-mode = "reg_read";
	qcom,mdss-dsi-panel-status-command = [06 01 00 01 00 00 01 0a];
	qcom,mdss-dsi-panel-status-command-state = "dsi_hs_mode";
	qcom,mdss-dsi-panel-status-value = <0x9c>;
	qcom,mdss-dsi-panel-status-read-length = <1>;
};

&dsi_sw43404_amoled_fhd_plus_cmd {
	qcom,esd-check-enabled;
	qcom,mdss-dsi-panel-status-check-mode = "reg_read";
	qcom,mdss-dsi-panel-status-command = [06 01 00 01 00 00 01 0a];
	qcom,mdss-dsi-panel-status-command-state = "dsi_hs_mode";
	qcom,mdss-dsi-panel-status-value = <0x9c>;
	qcom,mdss-dsi-panel-status-read-length = <1>;
};

&dsi_dual_nt35597_truly_cmd {
	qcom,esd-check-enabled;
	qcom,mdss-dsi-panel-status-check-mode = "reg_read";
	qcom,mdss-dsi-panel-status-command = [06 01 00 01 00 00 01 0a];
	qcom,mdss-dsi-panel-status-command-state = "dsi_hs_mode";
	qcom,mdss-dsi-panel-status-value = <0x9c>;
	qcom,mdss-dsi-panel-status-read-length = <1>;
};

&dsi_dual_nt35597_truly_video {
	qcom,esd-check-enabled;
	qcom,mdss-dsi-panel-status-check-mode = "reg_read";
	qcom,mdss-dsi-panel-status-command = [06 01 00 01 00 00 01 0a];
	qcom,mdss-dsi-panel-status-command-state = "dsi_hs_mode";
	qcom,mdss-dsi-panel-status-value = <0x9c>;
	qcom,mdss-dsi-panel-status-read-length = <1>;
};

&dsi_nt35597_truly_dsc_cmd {
	qcom,esd-check-enabled;
	qcom,mdss-dsi-panel-status-check-mode = "reg_read";
	qcom,mdss-dsi-panel-status-command = [06 01 00 01 00 00 01 0a];
	qcom,mdss-dsi-panel-status-command-state = "dsi_hs_mode";
	qcom,mdss-dsi-panel-status-value = <0x9c>;
	qcom,mdss-dsi-panel-status-read-length = <1>;
};

&dsi_nt35597_truly_dsc_video {
	qcom,esd-check-enabled;
	qcom,mdss-dsi-panel-status-check-mode = "reg_read";
	qcom,mdss-dsi-panel-status-command = [06 01 00 01 00 00 01 0a];
	qcom,mdss-dsi-panel-status-command-state = "dsi_hs_mode";
	qcom,mdss-dsi-panel-status-value = <0x9c>;
	qcom,mdss-dsi-panel-status-read-length = <1>;
};

&alioth_led {
	compatible = "pmic-pon";
	status = "ok";
	label = "charging";
	pinctrl-names = "default";
	pinctrl-0 = <&alioth_led_default>;
	qcom,use-blink;
	linux,default-trigger = "battery-charging";
};

&pm8150b_gpios {
	alioth_led {
		alioth_led_default: alioth_led_default {
			pins = "gpio3";
			function = "normal";
			output-high;
			bias-disable;
			power-source = <0>;
		};
	};
};
